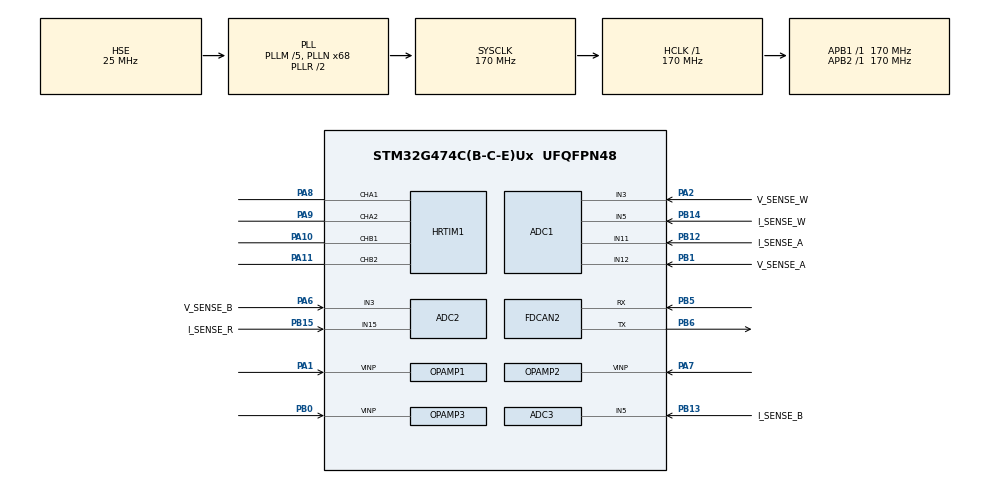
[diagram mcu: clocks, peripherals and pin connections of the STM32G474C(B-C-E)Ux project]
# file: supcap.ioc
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ADC1.Channel-0\#ChannelRegularConversion=ADC_CHANNEL_3
ADC1.Channel-1\#ChannelRegularConversion=ADC_CHANNEL_5
ADC1.Channel-2\#ChannelRegularConversion=ADC_CHANNEL_11
ADC1.Channel-3\#ChannelRegularConversion=ADC_CHANNEL_12
ADC1.DMAAccessModeView=ENABLE
ADC1.DMAContinuousRequests=ENABLE
ADC1.DiscontinuousConvMode=DISABLE
ADC1.EnableAnalogWatchDog1=false
ADC1.EnableAnalogWatchDog2=false
ADC1.ExternalTrigConv=ADC_EXTERNALTRIG_HRTIM_TRG1
ADC1.Mode=ADC_DUALMODE_REGSIMULT
ADC1.NbrOfConversion=4
ADC1.NbrOfConversionFlag=1
ADC1.OffsetNumber-0\#ChannelRegularConversion=ADC_OFFSET_NONE
ADC1.OffsetNumber-1\#ChannelRegularConversion=ADC_OFFSET_NONE
ADC1.OffsetNumber-2\#ChannelRegularConversion=ADC_OFFSET_NONE
ADC1.OffsetNumber-3\#ChannelRegularConversion=ADC_OFFSET_NONE
ADC1.Overrun=ADC_OVR_DATA_OVERWRITTEN
ADC1.Rank-0\#ChannelRegularConversion=1
ADC1.Rank-1\#ChannelRegularConversion=2
ADC1.Rank-2\#ChannelRegularConversion=3
ADC1.Rank-3\#ChannelRegularConversion=4
ADC1.SamplingTime-0\#ChannelRegularConversion=ADC_SAMPLETIME_6CYCLES_5
ADC1.SamplingTime-1\#ChannelRegularConversion=ADC_SAMPLETIME_6CYCLES_5
ADC1.SamplingTime-2\#ChannelRegularConversion=ADC_SAMPLETIME_6CYCLES_5
ADC1.SamplingTime-3\#ChannelRegularConversion=ADC_SAMPLETIME_6CYCLES_5
ADC1.master=1
ADC2.Channel-10\#ChannelRegularConversion=ADC_CHANNEL_15
ADC2.Channel-11\#ChannelRegularConversion=ADC_CHANNEL_15
ADC2.Channel-7\#ChannelRegularConversion=ADC_CHANNEL_3
ADC2.Channel-9\#ChannelRegularConversion=ADC_CHANNEL_3
ADC2.DMAAccessModeView=ENABLE
ADC2.DMAContinuousRequests=DISABLE
ADC2.EOCSelection=ADC_EOC_SINGLE_CONV
ADC2.EnableAnalogWatchDog1=false
ADC2.EnableAnalogWatchDog2=false
ADC2.EnableInjectedConversion=DISABLE
ADC2.EnableRegularConversion=ENABLE
ADC2.GainCompensation=0
ADC2.Mode=ADC_DUALMODE_REGSIMULT
ADC2.NbrOfConversion=4
ADC2.NbrOfConversionFlag=1
ADC2.OffsetNumber-10\#ChannelRegularConversion=ADC_OFFSET_NONE
ADC2.OffsetNumber-11\#ChannelRegularConversion=ADC_OFFSET_NONE
ADC2.OffsetNumber-7\#ChannelRegularConversion=ADC_OFFSET_NONE
ADC2.OffsetNumber-9\#ChannelRegularConversion=ADC_OFFSET_NONE
ADC2.Overrun=ADC_OVR_DATA_OVERWRITTEN
ADC2.OversamplingMode=DISABLE
ADC2.Rank-10\#ChannelRegularConversion=3
ADC2.Rank-11\#ChannelRegularConversion=4
ADC2.Rank-7\#ChannelRegularConversion=1
ADC2.Rank-9\#ChannelRegularConversion=2
ADC2.Rank1_Channel=ADC_CHANNEL_3
ADC2.SamplingTime-10\#ChannelRegularConversion=ADC_SAMPLETIME_6CYCLES_5
ADC2.SamplingTime-11\#ChannelRegularConversion=ADC_SAMPLETIME_6CYCLES_5
ADC2.SamplingTime-7\#ChannelRegularConversion=ADC_SAMPLETIME_6CYCLES_5
ADC2.SamplingTime-9\#ChannelRegularConversion=ADC_SAMPLETIME_6CYCLES_5
ADC3.Channel-0\#ChannelRegularConversion=ADC_CHANNEL_5
ADC3.DMAContinuousRequests=ENABLE
ADC3.EnableAnalogWatchDog1=false
ADC3.ExternalTrigConv=ADC_EXTERNALTRIG_HRTIM_TRG3
ADC3.NbrOfConversion=1
ADC3.NbrOfConversionFlag=1
ADC3.OffsetNumber-0\#ChannelRegularConversion=ADC_OFFSET_NONE
ADC3.Overrun=ADC_OVR_DATA_OVERWRITTEN
ADC3.Rank-0\#ChannelRegularConversion=1
ADC3.SamplingTime-0\#ChannelRegularConversion=ADC_SAMPLETIME_6CYCLES_5
ADC3.master=1
Dma.ADC1.0.Direction=DMA_PERIPH_TO_MEMORY
Dma.ADC1.0.EventEnable=DISABLE
Dma.ADC1.0.Instance=DMA1_Channel1
Dma.ADC1.0.MemDataAlignment=DMA_MDATAALIGN_WORD
Dma.ADC1.0.MemInc=DMA_MINC_ENABLE
Dma.ADC1.0.Mode=DMA_CIRCULAR
Dma.ADC1.0.PeriphDataAlignment=DMA_PDATAALIGN_WORD
Dma.ADC1.0.PeriphInc=DMA_PINC_DISABLE
Dma.ADC1.0.Polarity=HAL_DMAMUX_REQ_GEN_RISING
Dma.ADC1.0.Priority=DMA_PRIORITY_VERY_HIGH
Dma.ADC1.0.RequestNumber=1
Dma.ADC1.0.SignalID=NONE
Dma.ADC1.0.SyncEnable=DISABLE
Dma.ADC1.0.SyncPolarity=HAL_DMAMUX_SYNC_NO_EVENT
Dma.ADC1.0.SyncRequestNumber=1
Dma.ADC1.0.SyncSignalID=NONE
Dma.ADC3.1.Direction=DMA_PERIPH_TO_MEMORY
Dma.ADC3.1.EventEnable=DISABLE
Dma.ADC3.1.Instance=DMA1_Channel3
Dma.ADC3.1.MemDataAlignment=DMA_MDATAALIGN_WORD
Dma.ADC3.1.MemInc=DMA_MINC_ENABLE
Dma.ADC3.1.Mode=DMA_CIRCULAR
Dma.ADC3.1.PeriphDataAlignment=DMA_PDATAALIGN_WORD
Dma.ADC3.1.PeriphInc=DMA_PINC_DISABLE
Dma.ADC3.1.Polarity=HAL_DMAMUX_REQ_GEN_RISING
Dma.ADC3.1.Priority=DMA_PRIORITY_VERY_HIGH
Dma.ADC3.1.RequestNumber=1
Dma.ADC3.1.SignalID=NONE
Dma.ADC3.1.SyncEnable=DISABLE
Dma.ADC3.1.SyncPolarity=HAL_DMAMUX_SYNC_NO_EVENT
Dma.ADC3.1.SyncRequestNumber=1
Dma.ADC3.1.SyncSignalID=NONE
Dma.Request0=ADC1
Dma.Request1=ADC3
FDCAN2.CalculateBaudRateNominal=1000000
FDCAN2.CalculateTimeBitNominal=1000
FDCAN2.CalculateTimeQuantumNominal=100.0
FDCAN2.NominalPrescaler=17
FDCAN2.NominalTimeSeg1=7
FDCAN2.NominalTimeSeg2=2
FDCAN2.StdFiltersNbr=1
HRTIM1.ADCTrigger1_Source1=HRTIM_ADCTRIGGEREVENT13_MASTER_CMP1
HRTIM1.ADCTrigger3_Source1=HRTIM_ADCTRIGGEREVENT13_MASTER_CMP2
HRTIM1.ADCTrigger_Id1=HRTIM_ADCTRIGGER_1
HRTIM1.ADCTrigger_Id3=HRTIM_ADCTRIGGER_3
HRTIM1.CompareUnit1-MasterTimer=HRTIM_COMPAREUNIT_1
HRTIM1.CompareUnit1-Output_TA1TA2=HRTIM_COMPAREUNIT_1
HRTIM1.CompareUnit1-Output_TB1TB2=HRTIM_COMPAREUNIT_1
HRTIM1.CompareUnit2-MasterTimer=HRTIM_COMPAREUNIT_2
HRTIM1.CompareUnit2-Output_TA1TA2=__NULL
HRTIM1.CompareUnit2-Output_TB1TB2=__NULL
HRTIM1.CompareUnit3-MasterTimer=HRTIM_COMPAREUNIT_3
HRTIM1.CompareUnit3-Output_TA1TA2=HRTIM_COMPAREUNIT_3
HRTIM1.CompareUnit3-Output_TB1TB2=HRTIM_COMPAREUNIT_3
HRTIM1.CompareUnit4-Output_TA1TA2=__NULL
HRTIM1.CompareValue1-MasterTimer=5000-128
HRTIM1.CompareValue1-Output_TA1TA2=0
HRTIM1.CompareValue1-Output_TB1TB2=0
HRTIM1.CompareValue2-MasterTimer=15000-128
HRTIM1.CompareValue3-MasterTimer=10000
HRTIM1.DeadTimeInsertion-Output_TA1TA2=HRTIM_TIMDEADTIMEINSERTION_ENABLED
HRTIM1.DeadTimeInsertion-Output_TB1TB2=HRTIM_TIMDEADTIMEINSERTION_ENABLED
HRTIM1.Event_EEV1=__NULL
HRTIM1.Event_EEV2=__NULL
HRTIM1.Event_EEV3=__NULL
HRTIM1.Event_EEV4=__NULL
HRTIM1.Event_EEV5=__NULL
HRTIM1.Event_EEV6=__NULL
HRTIM1.Event_EEV7=__NULL
HRTIM1.FallingValue-Output_TA1TA2=100
HRTIM1.FallingValue-Output_TB1TB2=100
HRTIM1.Fault_Line1=__NULL
HRTIM1.Fault_Line2=__NULL
HRTIM1.Fault_Line3=__NULL
HRTIM1.Fault_Line4=__NULL
HRTIM1.InterruptRequests1_Master=HRTIM_MASTER_IT_MUPD
HRTIM1.NumberADCTriggerSource1=1
HRTIM1.NumberADCTriggerSource3=1
HRTIM1.NumberInterruptRequests_Master-MasterTimer=1
HRTIM1.NumberResetSource1-Output_TA1TA2=1
HRTIM1.NumberResetSource1-Output_TB1TB2=1
HRTIM1.NumberResetTrigger-Output_TA1TA2=1
HRTIM1.NumberResetTrigger-Output_TB1TB2=1
HRTIM1.NumberSetSource1-Output_TA1TA2=1
HRTIM1.NumberSetSource1-Output_TB1TB2=1
HRTIM1.NumberUpdateTrigger-Output_TA1TA2=1
HRTIM1.NumberUpdateTrigger-Output_TB1TB2=1
HRTIM1.ORingUpdateSource_ADCTrigger1=HRTIM_ADCTRIGGERUPDATE_MASTER
HRTIM1.Periode_MASTER=20000
HRTIM1.Periode_TA=20000
HRTIM1.Periode_TB=20000
HRTIM1.RepetitionCounter-MasterTimer=7
HRTIM1.RepetitionUpdate-MasterTimer=HRTIM_UPDATEONREPETITION_ENABLED
HRTIM1.RepetitionUpdate-Output_TA1TA2=HRTIM_UPDATEONREPETITION_ENABLED
HRTIM1.ResetOutput1_Source1-Output_TA1TA2=HRTIM_OUTPUTRESET_TIMCMP1
HRTIM1.ResetOutput1_Source1-Output_TB1TB2=HRTIM_OUTPUTRESET_TIMCMP1
HRTIM1.ResetTrigger1-Output_TA1TA2=HRTIM_TIMRESETTRIGGER_MASTER_PER
HRTIM1.ResetTrigger1-Output_TB1TB2=HRTIM_TIMRESETTRIGGER_MASTER_CMP3
HRTIM1.RisingValue-Output_TA1TA2=100
HRTIM1.RisingValue-Output_TB1TB2=100
HRTIM1.SetOutput1_Source1-Output_TA1TA2=HRTIM_OUTPUTSET_TIMCMP3
HRTIM1.SetOutput1_Source1-Output_TB1TB2=HRTIM_OUTPUTSET_TIMCMP3
HRTIM1.Timeout=10
HRTIM1.UpdateTrigger1-Output_TA1TA2=HRTIM_TIMUPDATETRIGGER_TIMER_A
HRTIM1.UpdateTrigger1-Output_TB1TB2=HRTIM_TIMUPDATETRIGGER_TIMER_B
IWDG.Prescaler=IWDG_PRESCALER_64
IWDG.Reload=1000
IWDG.Window=1000
Mcu.Family=STM32G4
Mcu.Name=STM32G474C(B-C-E)Ux
Mcu.Package=UFQFPN48
NVIC.FDCAN2_IT0_IRQn=true\:7\:0\:true\:false\:false\:true\:true\:true
NVIC.HRTIM1_Master_IRQn=true\:0\:0\:true\:false\:false\:true\:true\:true
NVIC.PriorityGroup=NVIC_PRIORITYGROUP_4
NVIC.TIM2_IRQn=true\:2\:0\:true\:false\:false\:true\:true\:true
PA1.Mode=Follower
PA1.Signal=OPAMP1_VINP
PA10.Mode=Output_TB1TB2
PA10.Signal=HRTIM1_CHB1
PA11.Mode=Output_TB1TB2
PA11.Signal=HRTIM1_CHB2
PA13.Mode=Serial_Wire
PA13.Signal=SYS_JTMS-SWDIO
PA14.Mode=Serial_Wire
PA14.Signal=SYS_JTCK-SWCLK
PA2.GPIO_Label=V_SENSE_W
PA2.Signal=SharedAnalog_PA2
PA6.GPIO_Label=V_SENSE_B
PA6.Signal=SharedAnalog_PA6
PA7.Mode=Follower
PA7.Signal=OPAMP2_VINP
PA8.Mode=Output_TA1TA2
PA8.Signal=HRTIM1_CHA1
PA9.Mode=Output_TA1TA2
PA9.Signal=HRTIM1_CHA2
PB0.Mode=Follower
PB0.Signal=OPAMP3_VINP
PB1.GPIO_Label=V_SENSE_A
PB1.Signal=SharedAnalog_PB1
PB12.GPIO_Label=I_SENSE_A
PB12.Mode=IN11-Single-Ended
PB12.Signal=ADC1_IN11
PB13.GPIO_Label=I_SENSE_B
PB13.Mode=IN5-Single-Ended
PB13.Signal=ADC3_IN5
PB14.GPIO_Label=I_SENSE_W
PB14.Mode=IN5-Single-Ended
PB14.Signal=ADC1_IN5
PB15.GPIO_Label=I_SENSE_R
PB15.Mode=IN15-Single-Ended
PB15.Signal=ADC2_IN15
PB5.Mode=FDCAN_Activate
PB5.Signal=FDCAN2_RX
PB6.Mode=FDCAN_Activate
PB6.Signal=FDCAN2_TX
PF0-OSC_IN.Mode=HSE-External-Oscillator
PF0-OSC_IN.Signal=RCC_OSC_IN
PF1-OSC_OUT.Mode=HSE-External-Oscillator
PF1-OSC_OUT.Signal=RCC_OSC_OUT
ProjectManager.HeapSize=0x200
ProjectManager.StackSize=0x400
ProjectManager.TargetToolchain=Makefile
RCC.ADC12Freq_Value=170000000
RCC.ADC345Freq_Value=170000000
RCC.AHBFreq_Value=170000000
RCC.APB1Freq_Value=170000000
RCC.APB1TimFreq_Value=170000000
RCC.APB2Freq_Value=170000000
RCC.APB2TimFreq_Value=170000000
RCC.CortexFreq_Value=170000000
RCC.EXTERNAL_CLOCK_VALUE=12288000
RCC.HCLKFreq_Value=170000000
RCC.HSE_VALUE=25000000
RCC.HSI48_VALUE=48000000
RCC.HSI_VALUE=16000000
RCC.LSE_VALUE=32768
RCC.PLLM=RCC_PLLM_DIV5
RCC.PLLN=68
RCC.PLLSourceVirtual=RCC_PLLSOURCE_HSE
RCC.SYSCLKFreq_VALUE=170000000
RCC.SYSCLKSource=RCC_SYSCLKSOURCE_PLLCLK
RCC.USBFreq_Value=170000000
RCC.VCOOutputFreq_Value=340000000
SH.SharedAnalog_PA2.0=ADC1_IN3,IN3-Single-Ended
SH.SharedAnalog_PA2.1=OPAMP1_VOUT,Follower
SH.SharedAnalog_PA6.0=ADC2_IN3,IN3-Single-Ended
SH.SharedAnalog_PA6.1=OPAMP2_VOUT,Follower
SH.SharedAnalog_PB1.0=ADC1_IN12,IN12-Single-Ended
SH.SharedAnalog_PB1.1=OPAMP3_VOUT,Follower
SYS.VoltageScaling=SYSCFG_VREFBUF_VOLTAGE_SCALE2
TIM2.PeriodNoDither=24
TIM2.Prescaler=1699
VP_HRTIM1_VS_hrtimMasterTimerNoOutput.Mode=MasterTimer
VP_IWDG_VS_IWDG.Mode=IWDG_Activate
VP_SYS_VS_DBSignals.Mode=DisableDeadBatterySignals
VP_TIM16_VS_ClockSourceINT.Mode=Enable_Timer
VP_TIM2_VS_ClockSourceINT.Mode=Internal
VREF+.Mode=InternalMode
VREF+.Signal=VREFBUF_OUT
board=custom

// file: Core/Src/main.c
/* USER CODE BEGIN Header */
/**
  ******************************************************************************
  * @file           : main.c
  * @brief          : Main program body
  ******************************************************************************
  * @attention
  *
  * Copyright (c) 2026 STMicroelectronics.
  * All rights reserved.
  *
  * This software is licensed under terms that can be found in the LICENSE file
  * in the root directory of this software component.
  * If no LICENSE file comes with this software, it is provided AS-IS.
  *
  ******************************************************************************
  */
/* USER CODE END Header */
#include "main.h"
#include "adc.h"
#include "dma.h"
#include "fdcan.h"
#include "hrtim.h"
#include "iwdg.h"
#include "opamp.h"
#include "tim.h"
#include "gpio.h"

void SystemClock_Config(void);
/* USER CODE BEGIN PFP */
extern void systemStart();
/* USER CODE END PFP */

int main(void)
{

  /* MCU Configuration--------------------------------------------------------*/

  /* Reset of all peripherals, Initializes the Flash interface and the Systick. */
  HAL_Init();

  /* Configure the system clock */
  SystemClock_Config();

  /* Initialize all configured peripherals */
  MX_GPIO_Init();
  MX_DMA_Init();
  MX_ADC1_Init();
  MX_ADC2_Init();
  MX_ADC3_Init();
  MX_FDCAN2_Init();
  MX_HRTIM1_Init();
  MX_OPAMP1_Init();
  MX_OPAMP2_Init();
  MX_OPAMP3_Init();
  MX_TIM2_Init();
  MX_IWDG_Init();
  MX_TIM16_Init();
  /* USER CODE BEGIN 2 */
  systemStart();
  /* USER CODE END 2 */

  /* Infinite loop */
  while (1)
  {

  }
}

void SystemClock_Config(void)
{
  RCC_OscInitTypeDef RCC_OscInitStruct = {0};
  RCC_ClkInitTypeDef RCC_ClkInitStruct = {0};

  /** Configure the main internal regulator output voltage
  */
  HAL_PWREx_ControlVoltageScaling(PWR_REGULATOR_VOLTAGE_SCALE1_BOOST);

  /** Initializes the RCC Oscillators according to the specified parameters
  * in the RCC_OscInitTypeDef structure.
  */
  RCC_OscInitStruct.OscillatorType = RCC_OSCILLATORTYPE_LSI|RCC_OSCILLATORTYPE_HSE;
  RCC_OscInitStruct.HSEState = RCC_HSE_ON;
  RCC_OscInitStruct.LSIState = RCC_LSI_ON;
  RCC_OscInitStruct.PLL.PLLState = RCC_PLL_ON;
  RCC_OscInitStruct.PLL.PLLSource = RCC_PLLSOURCE_HSE;
  RCC_OscInitStruct.PLL.PLLM = RCC_PLLM_DIV5;
  RCC_OscInitStruct.PLL.PLLN = 68;
  RCC_OscInitStruct.PLL.PLLP = RCC_PLLP_DIV2;
  RCC_OscInitStruct.PLL.PLLQ = RCC_PLLQ_DIV2;
  RCC_OscInitStruct.PLL.PLLR = RCC_PLLR_DIV2;
  if (HAL_RCC_OscConfig(&RCC_OscInitStruct) != HAL_OK)
  {
    Error_Handler();
  }

  /** Initializes the CPU, AHB and APB buses clocks
  */
  RCC_ClkInitStruct.ClockType = RCC_CLOCKTYPE_HCLK|RCC_CLOCKTYPE_SYSCLK
                              |RCC_CLOCKTYPE_PCLK1|RCC_CLOCKTYPE_PCLK2;
  RCC_ClkInitStruct.SYSCLKSource = RCC_SYSCLKSOURCE_PLLCLK;
  RCC_ClkInitStruct.AHBCLKDivider = RCC_SYSCLK_DIV1;
  RCC_ClkInitStruct.APB1CLKDivider = RCC_HCLK_DIV1;
  RCC_ClkInitStruct.APB2CLKDivider = RCC_HCLK_DIV1;

  if (HAL_RCC_ClockConfig(&RCC_ClkInitStruct, FLASH_LATENCY_4) != HAL_OK)
  {
    Error_Handler();
  }
}

void Error_Handler(void)
{
  __disable_irq();
  while (1)
  {
  }
}
